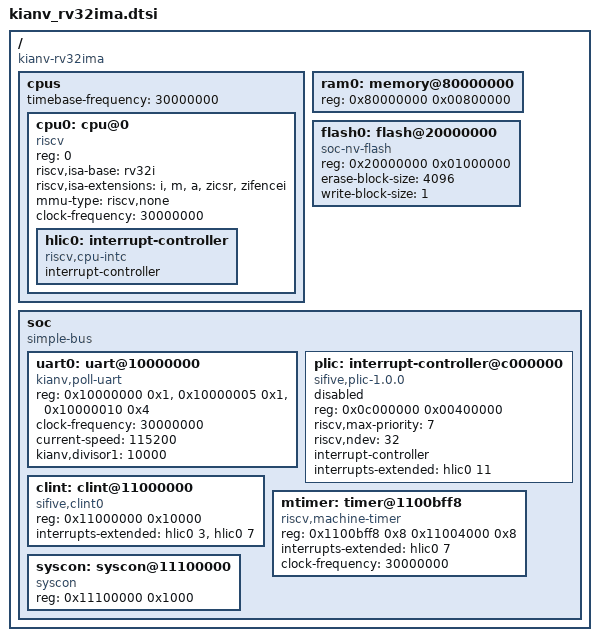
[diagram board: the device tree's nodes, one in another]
// SPDX-License-Identifier: Apache-2.0
/* Copyright (c) 2026 Hirosh Dabui <hirosh@dabui.de> */

#include <skeleton.dtsi>

/ {
	#address-cells = <1>;
	#size-cells = <1>;
	compatible = "kianv-rv32ima";

	cpus {
		#address-cells = <1>;
		#size-cells = <0>;
		timebase-frequency = <30000000>;

		cpu0: cpu@0 {
			device_type = "cpu";
			reg = <0>;
			status = "okay";
			compatible = "riscv";
			riscv,isa-base = "rv32i";
			riscv,isa-extensions = "i", "m", "a", "zicsr", "zifencei";
			mmu-type = "riscv,none";
			clock-frequency = <30000000>;

			hlic0: interrupt-controller {
				compatible = "riscv,cpu-intc";
				#address-cells = <0>;
				#interrupt-cells = <1>;
				interrupt-controller;
			};
		};
	};

	ram0: memory@80000000 {
		device_type = "memory";
		reg = <0x80000000 0x00800000>;
	};

	flash0: flash@20000000 {
		compatible = "soc-nv-flash";
		reg = <0x20000000 0x01000000>;
		erase-block-size = <4096>;
		write-block-size = <1>;
	};

	soc {
		#address-cells = <1>;
		#size-cells = <1>;
		compatible = "simple-bus";
		ranges;

		uart0: uart@10000000 {
			compatible = "kianv,poll-uart";
			reg = <0x10000000 0x1>,
			      <0x10000005 0x1>,
			      <0x10000010 0x4>;
			reg-names = "data", "lsr", "div";
			clock-frequency = <30000000>;
			current-speed = <115200>;
			kianv,divisor1 = <10000>;
			status = "okay";
		};

		plic: interrupt-controller@c000000 {
			compatible = "sifive,plic-1.0.0";
			reg = <0x0c000000 0x00400000>;
			riscv,max-priority = <7>;
			riscv,ndev = <32>;
			interrupt-controller;
			#address-cells = <0>;
			#interrupt-cells = <2>;
			interrupts-extended = <&hlic0 11>;
			status = "disabled";
		};

		clint: clint@11000000 {
			compatible = "sifive,clint0";
			reg = <0x11000000 0x10000>;
			interrupts-extended = <&hlic0 3 &hlic0 7>;
			status = "okay";
		};

		mtimer: timer@1100bff8 {
			compatible = "riscv,machine-timer";
			reg = <0x1100bff8 0x8 0x11004000 0x8>;
			reg-names = "mtime", "mtimecmp";
			interrupts-extended = <&hlic0 7>;
			clock-frequency = <30000000>;
			status = "okay";
		};

		syscon: syscon@11100000 {
			compatible = "syscon";
			reg = <0x11100000 0x1000>;
			status = "okay";
		};
	};
};
